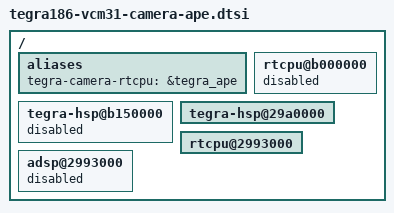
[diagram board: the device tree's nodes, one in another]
/*
 * tegra186-vcm31-camera-ape.dtsi: VCM3.1 board specific dtsi file for all VCM31 boards.
 *
 * Copyright (c) 2016, NVIDIA CORPORATION.  All rights reserved.
 *
 * This program is free software; you can redistribute it and/or modify
 * it under the terms of the GNU General Public License as published by
 * the Free Software Foundation; version 2 of the License.
 *
 * This program is distributed in the hope that it will be useful, but WITHOUT
 * ANY WARRANTY; without even the implied warranty of MERCHANTABILITY or
 * FITNESS FOR A PARTICULAR PURPOSE.  See the GNU General Public License for
 * more details.
 *
 */
/ {
	aliases {
		tegra-camera-rtcpu = &tegra_ape;
	};

	tegra-hsp@b150000 {
		status = "disabled";
	};

	rtcpu@b000000 {	/* not use SCE as camera-rtcpu */
		status = "disabled";
	};

	tegra-hsp@29a0000 {
		status = "okay";
	};

	rtcpu@2993000 {	/* use APE as camera-rtcpu */
		status = "okay";
	};

	adsp@2993000 {	/* not use APE as adsp */
		status = "disabled";
	};
};
